# PIC32MX270F256D device description
Architecture: MIPS; Family: PIC32MX; Series: PIC32MX
Registers are 32-bit, read-write, no defined reset value unless marked. A register's access mark holds for its fields unless they carry their own. Offsets are from the block's base; [hi:lo] are bit positions; {n}, {i} and the like mark numbered series.

## OSC
Instances: OSC 0x1f80f000 in periph1
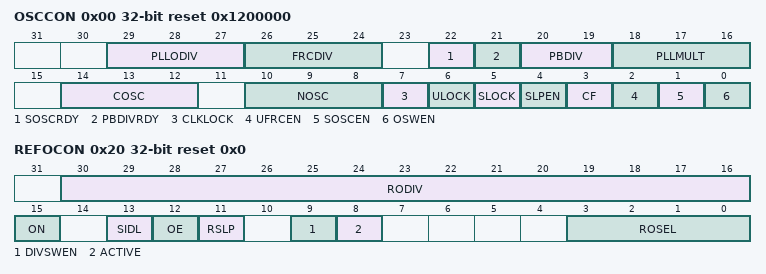
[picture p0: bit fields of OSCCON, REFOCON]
0x00 OSCCON reset 0x1200000 — Oscillator Control Register
  [29:27] PLLODIV — Output Divider for PLL
    7=DIV_256 (PLL output divided by 256); 6=DIV_64 (PLL output divided by 64); 5=DIV_32 (PLL output divided by 32); 4=DIV_16 (PLL output divided by 16); 3=DIV_8 (PLL output divided by 8); 2=DIV_4 (PLL output divided by 4); 1=DIV_2 (PLL output divided by 2); 0=DIV_1 (PLL output divided by 1)
  [26:24] FRCDIV — Internal Fast RC Oscillator Clock Divider bits
    7=DIV256 (FRC divided by 256); 6=DIV64 (FRC divided by 64); 5=DIV32 (FRC divided by 32); 4=DIV16 (FRC divided by 16); 3=DIV8 (FRC divided by 8); 2=DIV4 (FRC divided by 4); 1=DIV2 (FRC divided by 2 (default setting)); 0=DIV1 (FRC divided by 1)
  [22] SOSCRDY — Secondary Oscillator (SOSC) Ready Indicator bit
    1=READY (Indicates that the Secondary Oscillator is running and is stable); 0=NOT_READY (Secondary Oscillator is still warming up or is turned off)
  [21] PBDIVRDY — Peripheral Bus Clock Divisor Ready bit
    1=READY (PBDIV(1:0) bits can be written); 0=NOT_READY (PBDIV(1:0) bits cannot be written)
  [20:19] PBDIV — Peripheral Bus Clock (PBCLK) Divisor bits
    3=DIV_8 (PBCLK is SYSCLK divided by 8 (default)); 2=DIV_4 (PBCLK is SYSCLK divided by 4); 1=DIV_2 (PBCLK is SYSCLK divided by 2); 0=DIV_1 (PBCLK is SYSCLK divided by 1)
  [18:16] PLLMULT — Phase-Locked Loop (PLL) Multiplier bits
    7=MUL_24 (Clock is multiplied by 24); {v}=MUL_{v+15} (Clock is multiplied by {v+15}) (v=0..6)
  [14:12] COSC — Current Oscillator Selection bits
    7=FRCDIV (Internal Fast RC (FRC) Oscillator divided by OSCCON(FRCDIV) bits); 6=FRCDIV16 (Internal Fast RC (FRC) Oscillator divided by 16); 5=LPRC (Internal Low-Power RC (LPRC) Oscillator); 4=SOSC (Secondary Oscillator (SOSC)); 3=POSC_PLL (Primary Oscillator (POSC) with PLL module (XTPLL/HSPLL/ECPLL)); 2=POSC (Primary Oscillator (POSC) (XT/HS/EC)); 1=FRCPLL (Internal Fast RC Oscillator with PLL module via Postscaler (FRCPLL)); 0=FRC (Internal Fast RC (FRC) Oscillator)
  [10:8] NOSC — New Oscillator Selection bits
    7=FRCDIV (Internal Fast RC Oscillator (FRC) divided by OSCCON(FRCDIV) bits); 6=FRCDIV16 (Internal Fast RC Oscillator (FRC) divided by 16); 5=LPRC (Internal Low-Power RC (LPRC) Oscillator); 4=SOSC (Secondary Oscillator (SOSC)); 3=PRIPLL (Primary Oscillator with PLL module (XTPLL/HSPLL/ECPLL)); 2=PRI (Primary Oscillator (XT/HS/EC)); 1=FRCPLL (Internal Fast Internal RC Oscillator with PLL module via Postscaler (FRCPLL)); 0=FRC (Internal Fast Internal RC Oscillator (FRC))
  [7] CLKLOCK — Clock Selection Lock Enable bit
    1=ON ((If FCKSM(1:0) is 1x) Clock and PLL selections are locked / (If FCKSM(1:0) is 0x) Clock and PLL selections are never locked and may be modified); 0=OFF ((If FCKSM(1:0) is 1x) Clock and PLL selections are not locked and may be modified / (If FCKSM(1:0) is 0x) Clock and PLL selections are never locked and may be modified)
  [6] ULOCK — USB PLL Lock Status bit
    1=IN_LOCK (Indicates that the USB PLL module is in lock or USB PLL module start-up timer is satisfied); 0=OUT_LOCK (Indicates that the USB PLL module is out of lock or USB PLL module start-up timer is in progress or USB PLL is disabled)
  [5] SLOCK — PLL Lock Status bit
    1=IN_LOCK (PLL module is in lock or PLL module start-up timer is satisfied); 0=OUT_LOCK (PLL module is out of lock)
  [4] SLPEN — Sleep Mode Enable bit
    1=ENABLE (Device will enter Sleep mode when a WAIT instruction is executed); 0=DISABLE (Device will enter Idle mode when a WAIT instruction is executed)
  [3] CF — Clock Fail Detect bit
    1=DET (FSCM has detected a clock failure); 0=NO_DET (No clock failure has been detected)
  [2] UFRCEN — USB FRC Clock Enable bit
    1=FRC_EN (Enable FRC as the clock source for the USB clock source); 0=FRC_DIS (Use the Primary Oscillator or USB PLL as the USB clock source)
  [1] SOSCEN — Secondary Oscillator Enable bit
    1=ON (Enable Secondary Oscillator); 0=OFF (Disable Secondary Oscillator)
  [0] OSWEN — Oscillator Switch Enable bit
    1=ON (Initiate an oscillator switch to selection specified by NOSC(2:0) bits); 0=OFF (Oscillator switch is complete)
0x10 OSCTUN reset 0x0 — FRC Tuning Register
  [5:0] TUN — FRC Oscillator Tuning bits
    32=FREQ_MIN (Center frequency - 12.5%); 0=FREQ_CENTER (Center frequency. Oscillator runs at minimal frequency (8 MHz)); 31=FREQ_MAX (Center frequency + 12.5%)
0x20 REFOCON reset 0x0 — Reference Oscillator Control Register
  [30:16] RODIV — Reference Clock Divider bits
    0=NO_DIV (Reference Clock output is same as source clock); 1=DIV_2 (Reference Clock output is source clock divided by 2); 2=DIV_4 (Reference Clock output is source clock divided by 4); 0x7FFF=DIV_65534 (Reference Clock output is source clock divided by 65534)
  [15] ON — Output Enable bit
    1=ENABLE (Reference Oscillator Module is enabled); 0=DISABLE (Reference Oscillator Module is disabled)
  [13] SIDL — Peripheral Stop in Idle Mode bit
    1=ENABLE (Discontinue module operation when device enters Idle mode); 0=DISABLE (Continue module operation in Idle mode)
  [12] OE — Reference Clock Output Enable bit
    1=ENABLE (Reference clock is driven out on REFCLKO pin); 0=DISABLE (Reference clock is not driven out on REFCLKO pin)
  [11] RSLP — Reference Oscillator Module Run in Sleep bit
    1=ENABLE (Reference Oscillator Module output continues to run in Sleep); 0=DISABLE (Reference Oscillator Module output is disabled in Sleep)
  [9] DIVSWEN — Divider Switch Enable bit
    1=IN_PROGRESS (Divider switch is in progress); 0=DONE (Divider switch is complete)
  [8] ACTIVE — Reference Clock Request Status bit
    1=ACTIVE (Reference clock request is active); 0=INACTIVE (Reference clock request is not active)
  [3:0] ROSEL — Reference Clock Source Select bits
    {v}=Reserved; do not use (v=9..15); 8=REFCLKI; 7=Fvco Output; 6=USBPLL (USB PLL output); 5=SOSC; 4=LPRC; 3=FRC; 2=POSC; 1=PBCLK; 0=SYSCLK
0x30 REFOTRIM reset 0x0 — Reference Oscillator Trim Register
  [31:23] ROTRIM — Reference Oscillator Trim bits
    0x1ff=DIV_511 (511/512 divisor added to RODIV value); 0x1fe=DIV_510 (510/512 divisor added to RODIV value); 0x100=DIV_256 (256/512 divisor added to RODIV value); 2=DIV_2 (2/512 divisor added to RODIV value); 1=DIV_1 (1/512 divisor added to RODIV value); 0=DIV_0 (0/512 divisor added to RODIV value)
